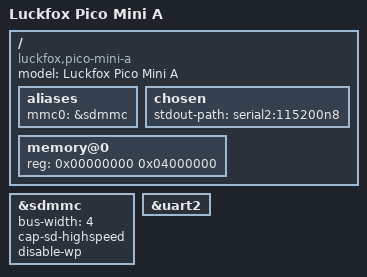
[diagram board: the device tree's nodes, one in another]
// SPDX-License-Identifier: (GPL-2.0+ OR MIT)
/*
 * Copyright (c) 2023 Luckfox Electronics Co., Ltd
 */

/dts-v1/;

#include "rv1103.dtsi"

/ {
	model = "Luckfox Pico Mini A";
	compatible = "luckfox,pico-mini-a", "rockchip,rv1103";

	aliases {
		mmc0 = &sdmmc;
	};

	chosen {
		stdout-path = "serial2:115200n8";
	};

	memory@0 {
		device_type = "memory";
		reg = <0x00000000 0x04000000>;
	};
};

&sdmmc {
	bus-width = <4>;
	cap-sd-highspeed;
	disable-wp;
	status = "okay";
};

&uart2 {
	status = "okay";
};
